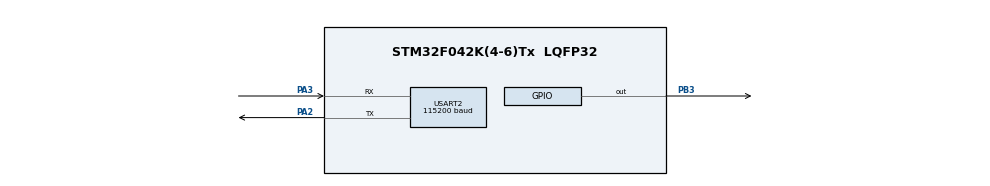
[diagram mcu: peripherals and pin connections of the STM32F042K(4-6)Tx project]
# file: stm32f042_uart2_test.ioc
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Mcu.Family=STM32F0
Mcu.Name=STM32F042K(4-6)Tx
Mcu.Package=LQFP32
PA2.Mode=Asynchronous
PA2.Signal=USART2_TX
PA3.Mode=Asynchronous
PA3.Signal=USART2_RX
PB3.Signal=GPIO_Output
ProjectManager.HeapSize=0x200
ProjectManager.StackSize=0x400
ProjectManager.TargetToolchain=SW4STM32
USART2.BaudRate=115200
USART2.VirtualMode-Asynchronous=VM_ASYNC
board=custom

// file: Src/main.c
/* USER CODE BEGIN Header */
/**
 ******************************************************************************
 * @file           : main.c
 * @brief          : Main program body
 ******************************************************************************
 * @attention
 *
 * <h2><center>&copy; Copyright (c) 2020 STMicroelectronics.
 * All rights reserved.</center></h2>
 *
 * This software component is licensed by ST under BSD 3-Clause license,
 * the "License"; You may not use this file except in compliance with the
 * License. You may obtain a copy of the License at:
 *                        opensource.org/licenses/BSD-3-Clause
 *
 ******************************************************************************
 */
/* USER CODE END Header */

#include "main.h"

UART_HandleTypeDef huart2;

void SystemClock_Config(void);
static void MX_GPIO_Init(void);
static void MX_USART2_UART_Init(void);

int main(void) {

    /* MCU Configuration--------------------------------------------------------*/

    /* Reset of all peripherals, Initializes the Flash interface and the Systick. */
    HAL_Init();

    /* Configure the system clock */
    SystemClock_Config();

    /* Initialize all configured peripherals */
    MX_GPIO_Init();
    MX_USART2_UART_Init();

    /* Infinite loop */
    while (1) {
        HAL_GPIO_TogglePin(GPIOB, GPIO_PIN_3);
        UU_PutString(USART2, "Hello World\r\n");
        HAL_Delay(500);
    }
}

void SystemClock_Config(void) {
    RCC_OscInitTypeDef RCC_OscInitStruct = { 0 };
    RCC_ClkInitTypeDef RCC_ClkInitStruct = { 0 };

    /** Initializes the CPU, AHB and APB busses clocks
     */
    RCC_OscInitStruct.OscillatorType = RCC_OSCILLATORTYPE_HSI;
    RCC_OscInitStruct.HSIState = RCC_HSI_ON;
    RCC_OscInitStruct.HSICalibrationValue = RCC_HSICALIBRATION_DEFAULT;
    RCC_OscInitStruct.PLL.PLLState = RCC_PLL_NONE;
    if (HAL_RCC_OscConfig(&RCC_OscInitStruct) != HAL_OK) {
        Error_Handler();
    }
    /** Initializes the CPU, AHB and APB busses clocks
     */
    RCC_ClkInitStruct.ClockType = RCC_CLOCKTYPE_HCLK | RCC_CLOCKTYPE_SYSCLK
            | RCC_CLOCKTYPE_PCLK1;
    RCC_ClkInitStruct.SYSCLKSource = RCC_SYSCLKSOURCE_HSI;
    RCC_ClkInitStruct.AHBCLKDivider = RCC_SYSCLK_DIV1;
    RCC_ClkInitStruct.APB1CLKDivider = RCC_HCLK_DIV1;

    if (HAL_RCC_ClockConfig(&RCC_ClkInitStruct, FLASH_LATENCY_0) != HAL_OK) {
        Error_Handler();
    }
}

static void MX_USART2_UART_Init(void) {

    huart2.Instance = USART2;
    huart2.Init.BaudRate = 115200;
    huart2.Init.WordLength = UART_WORDLENGTH_8B;
    huart2.Init.StopBits = UART_STOPBITS_1;
    huart2.Init.Parity = UART_PARITY_NONE;
    huart2.Init.Mode = UART_MODE_TX_RX;
    huart2.Init.HwFlowCtl = UART_HWCONTROL_NONE;
    huart2.Init.OverSampling = UART_OVERSAMPLING_16;
    huart2.Init.OneBitSampling = UART_ONE_BIT_SAMPLE_DISABLE;
    huart2.AdvancedInit.AdvFeatureInit = UART_ADVFEATURE_NO_INIT;
    if (HAL_UART_Init(&huart2) != HAL_OK) {
        Error_Handler();
    }

}

static void MX_GPIO_Init(void) {
    GPIO_InitTypeDef GPIO_InitStruct = { 0 };

    /* GPIO Ports Clock Enable */
    __HAL_RCC_GPIOA_CLK_ENABLE()
    ;
    __HAL_RCC_GPIOB_CLK_ENABLE()
    ;

    /*Configure GPIO pin Output Level */
    HAL_GPIO_WritePin(GPIOB, GPIO_PIN_3, GPIO_PIN_RESET);

    /*Configure GPIO pin : PB3 */
    GPIO_InitStruct.Pin = GPIO_PIN_3;
    GPIO_InitStruct.Mode = GPIO_MODE_OUTPUT_PP;
    GPIO_InitStruct.Pull = GPIO_NOPULL;
    GPIO_InitStruct.Speed = GPIO_SPEED_FREQ_LOW;
    HAL_GPIO_Init(GPIOB, &GPIO_InitStruct);

}

/* USER CODE BEGIN 4 */
void UU_PutChar(USART_TypeDef* USARTx, uint8_t ch) {
    while (!(USARTx->ISR & USART_ISR_TXE))
        ;
    USARTx->TDR = ch;
}

void UU_PutString(USART_TypeDef* USARTx, uint8_t * str) {
    while (*str != 0) {
        UU_PutChar(USARTx, *str);
        str++;
    }
}
/* USER CODE END 4 */

void Error_Handler(void) {
}

/************************ (C) COPYRIGHT STMicroelectronics *****END OF FILE****/
